# STM32H7B3x register map
File version: 2.2
CPU: CM7 r0p1, little endian, MPU, FPU, 4 interrupt priority bits
Registers are 32-bit, read-write, reset 0x0 unless marked. A register's access mark holds for its fields unless they carry their own. Offsets are from the block's base; [hi:lo] are bit positions; {n}, {i} and the like mark numbered series.

## AC — Access control
Base 0xE000EF90
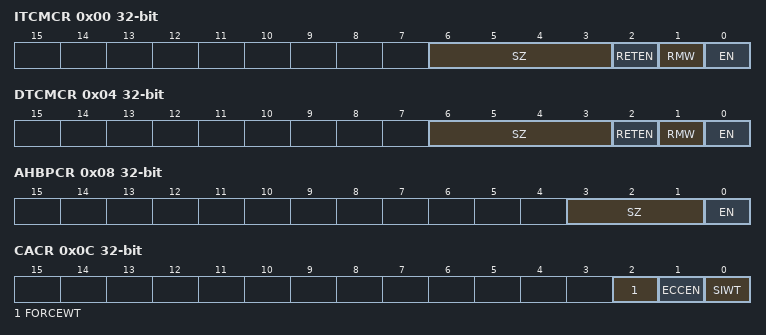
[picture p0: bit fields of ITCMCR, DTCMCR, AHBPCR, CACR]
0x00 ITCMCR — Instruction and Data Tightly-Coupled Memory Control Registers
  [6:3] SZ, [2] RETEN, [1] RMW, [0] EN
0x04 DTCMCR — Instruction and Data Tightly-Coupled Memory Control Registers
  [6:3] SZ, [2] RETEN, [1] RMW, [0] EN
0x08 AHBPCR — AHBP Control register
  [3:1] SZ, [0] EN
0x0C CACR — Auxiliary Cache Control register
  [2] FORCEWT, [1] ECCEN, [0] SIWT
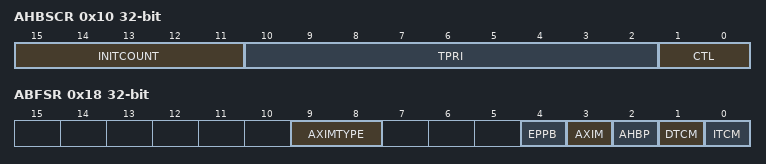
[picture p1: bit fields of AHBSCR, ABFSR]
0x10 AHBSCR — AHB Slave Control register
  [15:11] INITCOUNT, [10:2] TPRI, [1:0] CTL
0x18 ABFSR — Auxiliary Bus Fault Status register
  [9:8] AXIMTYPE, [4] EPPB, [3] AXIM, [2] AHBP, [1] DTCM, [0] ITCM

## COMP1
Base 0x58003800
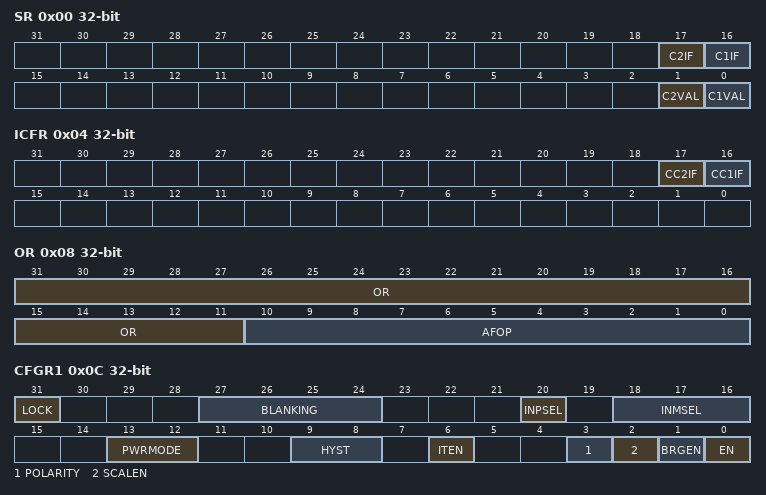
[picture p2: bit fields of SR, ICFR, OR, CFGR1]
0x00 SR ro — Comparator status register
  [17] C2IF — COMP channel 2 Interrupt Flag
  [16] C1IF — COMP channel 1 Interrupt Flag
  [1] C2VAL — COMP channel 2 output status bit
  [0] C1VAL — COMP channel 1 output status bit
0x04 ICFR wo — Comparator interrupt clear flag register
  [17] CC2IF — Clear COMP channel 2 Interrupt Flag
  [16] CC1IF — Clear COMP channel 1 Interrupt Flag
0x08 OR — Comparator option register
  [31:11] OR — Option Register
  [10:0] AFOP — Selection of source for alternate function of output ports
0x0C CFGR1 — Comparator configuration register 1
  [31] LOCK — Lock bit
  [27:24] BLANKING — COMP channel 1 blanking source selection bits
  [20] INPSEL — COMP channel 1 non-inverting input selection bit
  [18:16] INMSEL — COMP channel 1 inverting input selection field
  [13:12] PWRMODE — Power Mode of the COMP channel 1
  [9:8] HYST — COMP channel 1 hysteresis selection bits
  [6] ITEN — COMP channel 1 interrupt enable
  [3] POLARITY — COMP channel 1 polarity selection bit
  [2] SCALEN — Voltage scaler enable bit
  [1] BRGEN — Scaler bridge enable
  [0] EN — COMP channel 1 enable bit
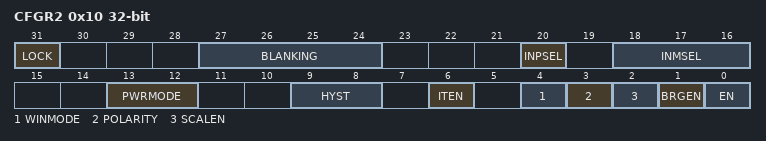
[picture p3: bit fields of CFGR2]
0x10 CFGR2 — Comparator configuration register 2
  [31] LOCK — Lock bit
  [27:24] BLANKING — COMP channel 1 blanking source selection bits
  [20] INPSEL — COMP channel 1 non-inverting input selection bit
  [18:16] INMSEL — COMP channel 1 inverting input selection field
  [13:12] PWRMODE — Power Mode of the COMP channel 1
  [9:8] HYST — COMP channel 1 hysteresis selection bits
  [6] ITEN — COMP channel 1 interrupt enable
  [4] WINMODE — Window comparator mode selection bit
  [3] POLARITY — COMP channel 1 polarity selection bit
  [2] SCALEN — Voltage scaler enable bit
  [1] BRGEN — Scaler bridge enable
  [0] EN — COMP channel 1 enable bit

## CRC — Cryptographic processor
Base 0x40023000
0x00 DR reset 0xFFFFFFFF — Data register
  [31:0] DR — Data Register
0x00 DR8 8-bit reset 0xFF (alternate view of DR) — Data register - byte sized
  [7:0] DR8 — Data register bits
0x00 DR16 16-bit reset 0xFFFF (alternate view of DR) — Data register - half-word sized
  [15:0] DR16 — Data register bits
0x04 IDR — Independent Data register
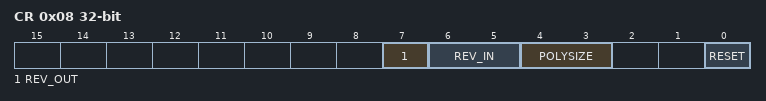
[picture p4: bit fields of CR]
0x08 CR access per field — Control register
  [7] REV_OUT rw — Reverse output data
    0=Normal (Bit order not affected); 1=Reversed (Bit reversed output)
  [6:5] REV_IN rw — Reverse input data
    0=Normal (Bit order not affected); 1=Byte (Bit reversal done by byte); 2=HalfWord (Bit reversal done by half-word); 3=Word (Bit reversal done by word)
  [4:3] POLYSIZE rw — Polynomial size
    0=32-bit polynomial; 1=16-bit polynomial; 2=8-bit polynomial; 3=7-bit polynomial
  [0] RESET wo — RESET bit
    on write: 1=Resets the CRC calculation unit and sets the data register to 0xFFFF FFFF
0x10 INIT — Initial CRC value
  [31:0] INIT — Programmable initial CRC value
0x14 POL — CRC polynomial
  [31:0] POL — Programmable polynomial

## CRYP — Cryptographic processor
Base 0x48021000
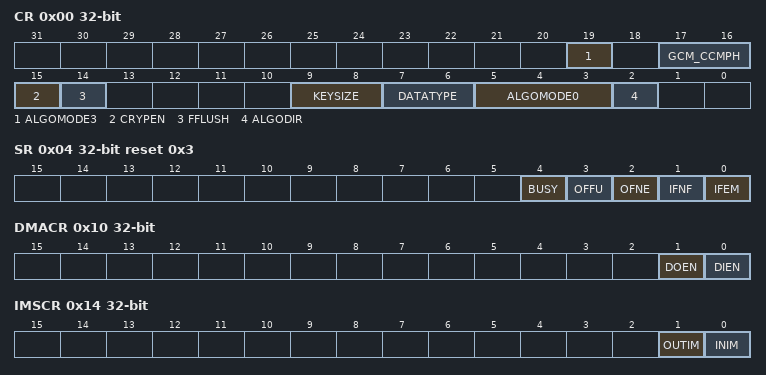
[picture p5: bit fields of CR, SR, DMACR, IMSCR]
0x00 CR access per field — control register
  [19] ALGOMODE3 rw — ALGOMODE
  [17:16] GCM_CCMPH rw
  [15] CRYPEN rw — Cryptographic processor enable
  [14] FFLUSH wo — FIFO flush
  [9:8] KEYSIZE rw — Key size selection (AES mode only)
  [7:6] DATATYPE rw — Data type selection
  [5:3] ALGOMODE0 rw — Algorithm mode
  [2] ALGODIR rw — Algorithm direction
0x04 SR ro reset 0x3 — status register
  [4] BUSY — Busy bit
  [3] OFFU — Output FIFO full
  [2] OFNE — Output FIFO not empty
  [1] IFNF — Input FIFO not full
  [0] IFEM — Input FIFO empty
0x08 DIN — data input register
  [31:0] DATAIN — Data input
0x0C DOUT ro — data output register
  [31:0] DATAOUT — Data output
0x10 DMACR — DMA control register
  [1] DOEN — DMA output enable
  [0] DIEN — DMA input enable
0x14 IMSCR — interrupt mask set/clear register
  [1] OUTIM — Output FIFO service interrupt mask
  [0] INIM — Input FIFO service interrupt mask
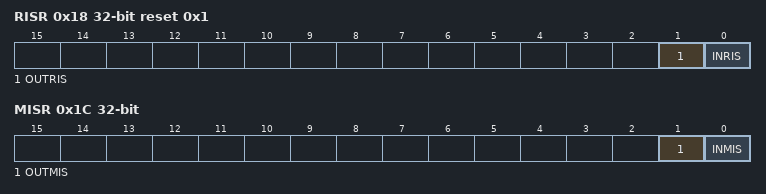
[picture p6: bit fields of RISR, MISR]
0x18 RISR ro reset 0x1 — raw interrupt status register
  [1] OUTRIS — Output FIFO service raw interrupt status
  [0] INRIS — Input FIFO service raw interrupt status
0x1C MISR ro — masked interrupt status register
  [1] OUTMIS — Output FIFO service masked interrupt status
  [0] INMIS — Input FIFO service masked interrupt status
0x20 K0LR wo — key registers
  [31:0] b2 — b224
0x24 K0RR wo — key registers
  [31:0] b — b192
0x28 K1LR wo — key registers
  [31:0] b1 — b160
0x2C K1RR wo — key registers
  [31:0] b1 — b128
0x30 K2LR wo — key registers
  [31:0] b — b96
0x34 K2RR wo — key registers
  [31:0] b — b64
0x38 K3LR wo — key registers
  [31:0] b — b32
0x3C K3RR wo — key registers
  [31:0] b — b0
0x40 IV0LR — initialization vector registers
  [31:0] IV — IV31
0x44 IV0RR — initialization vector registers
  [31:0] IV — IV63
0x48 IV1LR — initialization vector registers
  [31:0] IV — IV95
0x4C IV1RR — initialization vector registers
  [31:0] IV — IV127
{0x50+4i} CSGCMCCM{i}R (i=0..7) — context swap register
{0x70+4i} CSGCM{i}R (i=0..7) — context swap register
